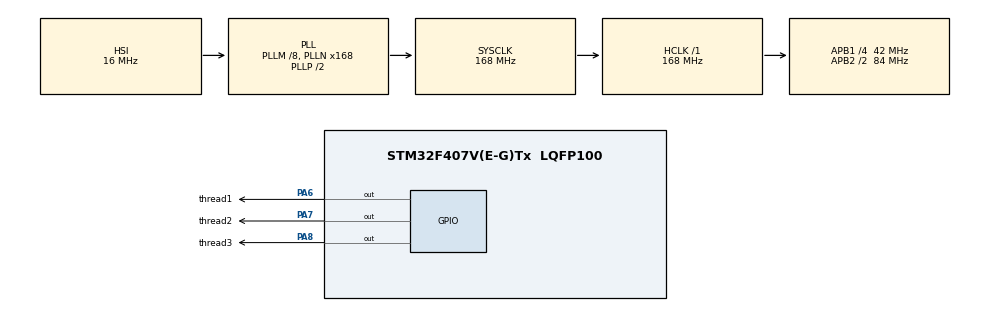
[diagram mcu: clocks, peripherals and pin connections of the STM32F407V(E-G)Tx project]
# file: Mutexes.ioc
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FREERTOS.Mutexes01=myMutex01,Dynamic,NULL
FREERTOS.Tasks01=defaultTask,0,128,StartDefaultTask,Default,NULL,Dynamic,NULL,NULL;Thread1,2,128,StartThread1,Default,NULL,Dynamic,NULL,NULL;Thread2,1,128,StartThread2,Default,NULL,Dynamic,NULL,NULL
Mcu.Family=STM32F4
Mcu.Name=STM32F407V(E-G)Tx
Mcu.Package=LQFP100
NVIC.PriorityGroup=NVIC_PRIORITYGROUP_4
PA13.Mode=JTAG_5_pins
PA13.Signal=SYS_JTMS-SWDIO
PA14.Mode=JTAG_5_pins
PA14.Signal=SYS_JTCK-SWCLK
PA15.Mode=JTAG_5_pins
PA15.Signal=SYS_JTDI
PA6.GPIO_Label=thread1
PA6.GPIO_PuPd=GPIO_PULLUP
PA6.GPIO_Speed=GPIO_SPEED_FREQ_HIGH
PA6.PinState=GPIO_PIN_SET
PA6.Signal=GPIO_Output
PA7.GPIO_Label=thread2
PA7.GPIO_PuPd=GPIO_PULLUP
PA7.GPIO_Speed=GPIO_SPEED_FREQ_HIGH
PA7.PinState=GPIO_PIN_SET
PA7.Signal=GPIO_Output
PA8.GPIO_Label=thread3
PA8.GPIO_PuPd=GPIO_PULLUP
PA8.GPIO_Speed=GPIO_SPEED_FREQ_HIGH
PA8.PinState=GPIO_PIN_SET
PA8.Signal=GPIO_Output
PB3.Mode=JTAG_5_pins
PB3.Signal=SYS_JTDO-SWO
PB4.Mode=JTAG_5_pins
PB4.Signal=SYS_JTRST
ProjectManager.HeapSize=0x200
ProjectManager.StackSize=0x400
ProjectManager.TargetToolchain=EWARM
RCC.48MHZClocksFreq_Value=84000000
RCC.AHBFreq_Value=168000000
RCC.APB1CLKDivider=RCC_HCLK_DIV4
RCC.APB1Freq_Value=42000000
RCC.APB1TimFreq_Value=84000000
RCC.APB2CLKDivider=RCC_HCLK_DIV2
RCC.APB2Freq_Value=84000000
RCC.APB2TimFreq_Value=168000000
RCC.CortexFreq_Value=168000000
RCC.HCLKFreq_Value=168000000
RCC.HSE_VALUE=25000000
RCC.HSI_VALUE=16000000
RCC.LSE_VALUE=32768
RCC.PLLM=8
RCC.PLLN=168
RCC.SYSCLKFreq_VALUE=168000000
RCC.SYSCLKSource=RCC_SYSCLKSOURCE_PLLCLK
RCC.VCOOutputFreq_Value=336000000
VP_FREERTOS_VS_ENABLE.Mode=Enabled
board=Mutexes

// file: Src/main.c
/**
  ******************************************************************************
  * File Name          : main.c
  * Description        : Main program body
  ******************************************************************************
  * This notice applies to any and all portions of this file
  * that are not between comment pairs USER CODE BEGIN and
  * USER CODE END. Other portions of this file, whether
  * inserted by the user or by software development tools
  * are owned by their respective copyright owners.
  *
  * Copyright (c) 2020 STMicroelectronics International N.V.
  * All rights reserved.
  *
  * Redistribution and use in source and binary forms, with or without
  * modification, are permitted, provided that the following conditions are met:
  *
  * 1. Redistribution of source code must retain the above copyright notice,
  *    this list of conditions and the following disclaimer.
  * 2. Redistributions in binary form must reproduce the above copyright notice,
  *    this list of conditions and the following disclaimer in the documentation
  *    and/or other materials provided with the distribution.
  * 3. Neither the name of STMicroelectronics nor the names of other
  *    contributors to this software may be used to endorse or promote products
  *    derived from this software without specific written permission.
  * 4. This software, including modifications and/or derivative works of this
  *    software, must execute solely and exclusively on microcontroller or
  *    microprocessor devices manufactured by or for STMicroelectronics.
  * 5. Redistribution and use of this software other than as permitted under
  *    this license is void and will automatically terminate your rights under
  *    this license.
  *
  * THIS SOFTWARE IS PROVIDED BY STMICROELECTRONICS AND CONTRIBUTORS "AS IS"
  * AND ANY EXPRESS, IMPLIED OR STATUTORY WARRANTIES, INCLUDING, BUT NOT
  * LIMITED TO, THE IMPLIED WARRANTIES OF MERCHANTABILITY, FITNESS FOR A
  * PARTICULAR PURPOSE AND NON-INFRINGEMENT OF THIRD PARTY INTELLECTUAL PROPERTY
  * RIGHTS ARE DISCLAIMED TO THE FULLEST EXTENT PERMITTED BY LAW. IN NO EVENT
  * SHALL STMICROELECTRONICS OR CONTRIBUTORS BE LIABLE FOR ANY DIRECT, INDIRECT,
  * INCIDENTAL, SPECIAL, EXEMPLARY, OR CONSEQUENTIAL DAMAGES (INCLUDING, BUT NOT
  * LIMITED TO, PROCUREMENT OF SUBSTITUTE GOODS OR SERVICES; LOSS OF USE, DATA,
  * OR PROFITS; OR BUSINESS INTERRUPTION) HOWEVER CAUSED AND ON ANY THEORY OF
  * LIABILITY, WHETHER IN CONTRACT, STRICT LIABILITY, OR TORT (INCLUDING
  * NEGLIGENCE OR OTHERWISE) ARISING IN ANY WAY OUT OF THE USE OF THIS SOFTWARE,
  * EVEN IF ADVISED OF THE POSSIBILITY OF SUCH DAMAGE.
  *
  ******************************************************************************
  */

#include "main.h"
#include "stm32f4xx_hal.h"
#include "cmsis_os.h"

osThreadId defaultTaskHandle;
osThreadId Thread1Handle;
osThreadId Thread2Handle;
osMutexId myMutex01Handle;

/* USER CODE BEGIN PV */
/* Private variables ---------------------------------------------------------*/

/* USER CODE END PV */

void SystemClock_Config(void);
static void MX_GPIO_Init(void);
void StartDefaultTask(void const * argument);
void StartThread1(void const * argument);
void StartThread2(void const * argument);

/* USER CODE BEGIN PFP */
/* Private function prototypes -----------------------------------------------*/

/* USER CODE END PFP */

/* USER CODE BEGIN 0 */
unsigned int counter1, counter2, counter3 = 0;

/* USER CODE END 0 */

int main(void)
{

  /* MCU Configuration----------------------------------------------------------*/

  /* Reset of all peripherals, Initializes the Flash interface and the Systick. */
  HAL_Init();

  /* Configure the system clock */
  SystemClock_Config();

  /* Initialize all configured peripherals */
  MX_GPIO_Init();

  /* USER CODE BEGIN 2 */
  counter1 = 0;
  counter2 = 0;
  counter3 = 0;
  /* USER CODE END 2 */

  /* Create the mutex(es) */
  /* definition and creation of myMutex01 */
  osMutexDef(myMutex01);
  myMutex01Handle = osMutexCreate(osMutex(myMutex01));

  /* Create the thread(s) */
  /* definition and creation of defaultTask */
  osThreadDef(defaultTask, StartDefaultTask, osPriorityNormal, 0, 128);
  defaultTaskHandle = osThreadCreate(osThread(defaultTask), NULL);

  /* definition and creation of Thread1 */
  osThreadDef(Thread1, StartThread1, osPriorityHigh, 0, 128);
  Thread1Handle = osThreadCreate(osThread(Thread1), NULL);

  /* definition and creation of Thread2 */
  osThreadDef(Thread2, StartThread2, osPriorityAboveNormal, 0, 128);
  Thread2Handle = osThreadCreate(osThread(Thread2), NULL);

  /* Start scheduler */
  osKernelStart();

  /* We should never get here as control is now taken by the scheduler */

  /* Infinite loop */
  while (1)
  {

  }

}

/** System Clock Configuration
*/
void SystemClock_Config(void)
{

  RCC_OscInitTypeDef RCC_OscInitStruct;
  RCC_ClkInitTypeDef RCC_ClkInitStruct;

    /**Configure the main internal regulator output voltage
    */
  __HAL_RCC_PWR_CLK_ENABLE();

  __HAL_PWR_VOLTAGESCALING_CONFIG(PWR_REGULATOR_VOLTAGE_SCALE1);

    /**Initializes the CPU, AHB and APB busses clocks
    */
  RCC_OscInitStruct.OscillatorType = RCC_OSCILLATORTYPE_HSI;
  RCC_OscInitStruct.HSIState = RCC_HSI_ON;
  RCC_OscInitStruct.HSICalibrationValue = 16;
  RCC_OscInitStruct.PLL.PLLState = RCC_PLL_ON;
  RCC_OscInitStruct.PLL.PLLSource = RCC_PLLSOURCE_HSI;
  RCC_OscInitStruct.PLL.PLLM = 8;
  RCC_OscInitStruct.PLL.PLLN = 168;
  RCC_OscInitStruct.PLL.PLLP = RCC_PLLP_DIV2;
  RCC_OscInitStruct.PLL.PLLQ = 4;
  if (HAL_RCC_OscConfig(&RCC_OscInitStruct) != HAL_OK)
  {
    _Error_Handler(__FILE__, __LINE__);
  }

    /**Initializes the CPU, AHB and APB busses clocks
    */
  RCC_ClkInitStruct.ClockType = RCC_CLOCKTYPE_HCLK|RCC_CLOCKTYPE_SYSCLK
                              |RCC_CLOCKTYPE_PCLK1|RCC_CLOCKTYPE_PCLK2;
  RCC_ClkInitStruct.SYSCLKSource = RCC_SYSCLKSOURCE_PLLCLK;
  RCC_ClkInitStruct.AHBCLKDivider = RCC_SYSCLK_DIV1;
  RCC_ClkInitStruct.APB1CLKDivider = RCC_HCLK_DIV4;
  RCC_ClkInitStruct.APB2CLKDivider = RCC_HCLK_DIV2;

  if (HAL_RCC_ClockConfig(&RCC_ClkInitStruct, FLASH_LATENCY_5) != HAL_OK)
  {
    _Error_Handler(__FILE__, __LINE__);
  }

    /**Configure the Systick interrupt time
    */
  HAL_SYSTICK_Config(HAL_RCC_GetHCLKFreq()/1000);

    /**Configure the Systick
    */
  HAL_SYSTICK_CLKSourceConfig(SYSTICK_CLKSOURCE_HCLK);

  /* SysTick_IRQn interrupt configuration */
  HAL_NVIC_SetPriority(SysTick_IRQn, 15, 0);
}

/** Configure pins as
        * Analog
        * Input
        * Output
        * EVENT_OUT
        * EXTI
*/
static void MX_GPIO_Init(void)
{

  GPIO_InitTypeDef GPIO_InitStruct;

  /* GPIO Ports Clock Enable */
  __HAL_RCC_GPIOA_CLK_ENABLE();
  __HAL_RCC_GPIOB_CLK_ENABLE();

  /*Configure GPIO pin Output Level */
  HAL_GPIO_WritePin(GPIOA, thread1_Pin|thread2_Pin|thread3_Pin, GPIO_PIN_SET);

  /*Configure GPIO pins : thread1_Pin thread2_Pin thread3_Pin */
  GPIO_InitStruct.Pin = thread1_Pin|thread2_Pin|thread3_Pin;
  GPIO_InitStruct.Mode = GPIO_MODE_OUTPUT_PP;
  GPIO_InitStruct.Pull = GPIO_PULLUP;
  GPIO_InitStruct.Speed = GPIO_SPEED_FREQ_HIGH;
  HAL_GPIO_Init(GPIOA, &GPIO_InitStruct);

}

/* StartDefaultTask function */
void StartDefaultTask(void const * argument)
{

  /* USER CODE BEGIN 5 */
  /* Infinite loop */

    for(;;)
    {
      ++counter3;
      osMutexWait(myMutex01Handle, 0);
      osMutexRelease(myMutex01Handle);
      osDelay(1);
    }

  /* USER CODE END 5 */
}

/* StartThread1 function */
void StartThread1(void const * argument)
{
  /* USER CODE BEGIN StartThread1 */
  /* Infinite loop */
  for(;;)
    {
      counter1++;
      osMutexWait(myMutex01Handle, 0);
      osMutexRelease(myMutex01Handle);
      osDelay(1);
    }
  /* USER CODE END StartThread1 */
}

/* StartThread2 function */
void StartThread2(void const * argument)
{
  /* USER CODE BEGIN StartThread2 */

  /* Infinite loop */
    for(;;)
    {
      counter2++;
      osMutexWait(myMutex01Handle, 0);
      osMutexRelease(myMutex01Handle);
      osDelay(1);
    }
  /* USER CODE END StartThread2 */
}

void _Error_Handler(char * file, int line)
{
  while(1)
  {
  }
}

/************************ (C) COPYRIGHT STMicroelectronics *****END OF FILE****/
